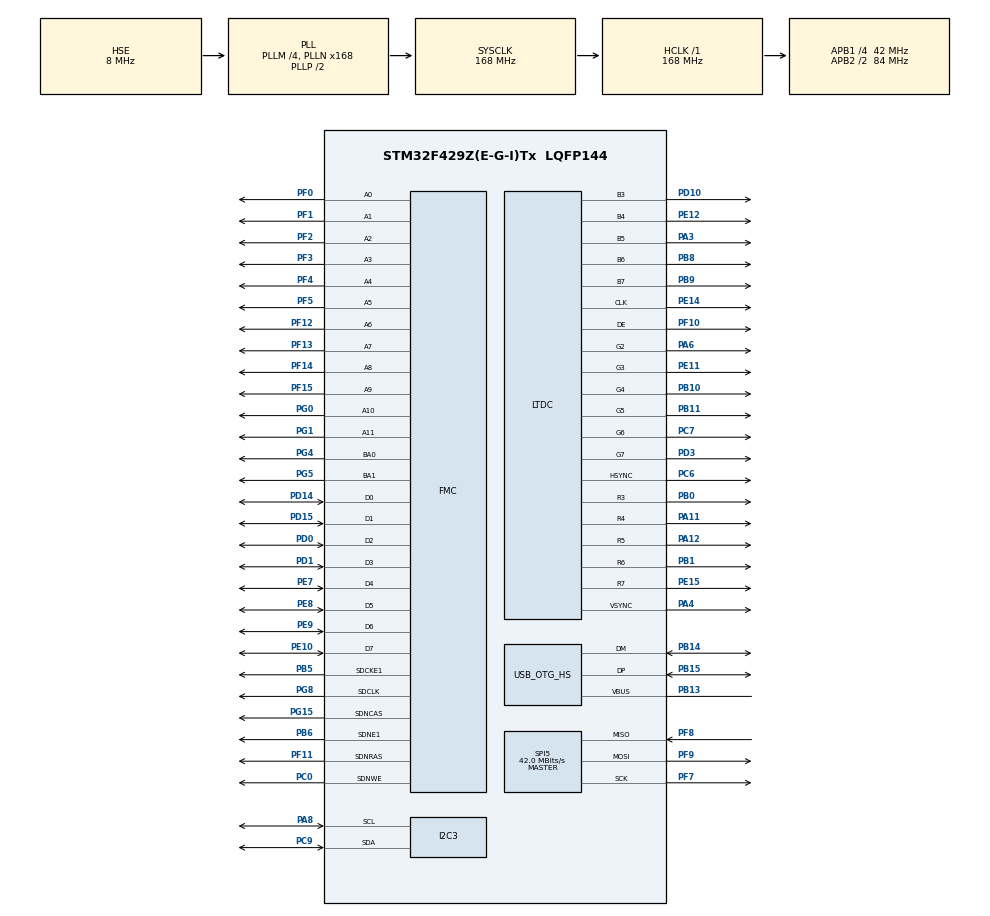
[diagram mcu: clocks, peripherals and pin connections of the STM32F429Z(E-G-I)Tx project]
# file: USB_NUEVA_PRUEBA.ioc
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DMA2D.ColorMode=DMA2D_OUTPUT_RGB565
FATFS._USE_STRFUNC=1
FREERTOS.Queues01=queue_usb,1,uint16_t,NULL,Dynamic,NULL,NULL
FREERTOS.Tasks01=USB,0,128,USB_TASK,Default,NULL,Dynamic,NULL,NULL;LCD,-3,128,LCD_TASK,Default,NULL,Dynamic,NULL,NULL
LTDC.ActiveH=240
LTDC.ActiveW=320
LTDC.PixelFormat_L0=LTDC_PIXEL_FORMAT_RGB565
LTDC.PixelFormat_L1=LTDC_PIXEL_FORMAT_RGB565
Mcu.Family=STM32F4
Mcu.Name=STM32F429Z(E-G-I)Tx
Mcu.Package=LQFP144
NVIC.OTG_HS_IRQn=true\:5\:0\:false\:false\:true\:true
NVIC.PriorityGroup=NVIC_PRIORITYGROUP_4
NVIC.TIM1_UP_TIM10_IRQn=true\:0\:0\:false\:false\:true\:false
NVIC.TimeBase=TIM1_UP_TIM10_IRQn
NVIC.TimeBaseIP=TIM1
PA11.Mode=RGB565
PA11.Signal=LTDC_R4
PA12.Mode=RGB565
PA12.Signal=LTDC_R5
PA13.Mode=Serial_Wire
PA13.Signal=SYS_JTMS-SWDIO
PA14.Mode=Serial_Wire
PA14.Signal=SYS_JTCK-SWCLK
PA3.Mode=RGB565
PA3.Signal=LTDC_B5
PA4.Mode=RGB565
PA4.Signal=LTDC_VSYNC
PA6.Mode=RGB565
PA6.Signal=LTDC_G2
PA8.Mode=I2C
PA8.Signal=I2C3_SCL
PB0.Mode=RGB565
PB0.Signal=LTDC_R3
PB1.Mode=RGB565
PB1.Signal=LTDC_R6
PB10.Mode=RGB565
PB10.Signal=LTDC_G4
PB11.Mode=RGB565
PB11.Signal=LTDC_G5
PB13.Mode=Activate_VBUS_FS
PB13.Signal=USB_OTG_HS_VBUS
PB14.Mode=Host_FS
PB14.Signal=USB_OTG_HS_DM
PB15.Mode=Host_FS
PB15.Signal=USB_OTG_HS_DP
PB5.Mode=SdramChipSelect2_1
PB5.Signal=FMC_SDCKE1
PB6.Mode=SdramChipSelect2_1
PB6.Signal=FMC_SDNE1
PB8.Mode=RGB565
PB8.Signal=LTDC_B6
PB9.Mode=RGB565
PB9.Signal=LTDC_B7
PC0.Signal=FMC_SDNWE
PC6.Mode=RGB565
PC6.Signal=LTDC_HSYNC
PC7.Mode=RGB565
PC7.Signal=LTDC_G6
PC9.Mode=I2C
PC9.Signal=I2C3_SDA
PD0.Signal=FMC_D2_DA2
PD1.Signal=FMC_D3_DA3
PD10.Mode=RGB565
PD10.Signal=LTDC_B3
PD14.Signal=FMC_D0_DA0
PD15.Signal=FMC_D1_DA1
PD3.Mode=RGB565
PD3.Signal=LTDC_G7
PE10.Signal=FMC_D7_DA7
PE11.Mode=RGB565
PE11.Signal=LTDC_G3
PE12.Mode=RGB565
PE12.Signal=LTDC_B4
PE14.Mode=RGB565
PE14.Signal=LTDC_CLK
PE15.Mode=RGB565
PE15.Signal=LTDC_R7
PE7.Signal=FMC_D4_DA4
PE8.Signal=FMC_D5_DA5
PE9.Signal=FMC_D6_DA6
PF0.Signal=FMC_A0
PF1.Signal=FMC_A1
PF10.Mode=RGB565
PF10.Signal=LTDC_DE
PF11.Signal=FMC_SDNRAS
PF12.Signal=FMC_A6
PF13.Signal=FMC_A7
PF14.Signal=FMC_A8
PF15.Signal=FMC_A9
PF2.Signal=FMC_A2
PF3.Signal=FMC_A3
PF4.Signal=FMC_A4
PF5.Signal=FMC_A5
PF7.Mode=Full_Duplex_Master
PF7.Signal=SPI5_SCK
PF8.Mode=Full_Duplex_Master
PF8.Signal=SPI5_MISO
PF9.Mode=Full_Duplex_Master
PF9.Signal=SPI5_MOSI
PG0.Signal=FMC_A10
PG1.Signal=FMC_A11
PG15.Signal=FMC_SDNCAS
PG4.Signal=FMC_A14_BA0
PG5.Signal=FMC_A15_BA1
PG8.Signal=FMC_SDCLK
PH0/OSC_IN.Mode=HSE-External-Oscillator
PH0/OSC_IN.Signal=RCC_OSC_IN
PH1/OSC_OUT.Mode=HSE-External-Oscillator
PH1/OSC_OUT.Signal=RCC_OSC_OUT
ProjectManager.HeapSize=0x200
ProjectManager.StackSize=0x400
ProjectManager.TargetToolchain=SW4STM32
RCC.48MHZClocksFreq_Value=48000000
RCC.AHBFreq_Value=168000000
RCC.APB1CLKDivider=RCC_HCLK_DIV4
RCC.APB1Freq_Value=42000000
RCC.APB1TimFreq_Value=84000000
RCC.APB2CLKDivider=RCC_HCLK_DIV2
RCC.APB2Freq_Value=84000000
RCC.APB2TimFreq_Value=168000000
RCC.CortexFreq_Value=168000000
RCC.HCLKFreq_Value=168000000
RCC.HSE_VALUE=8000000
RCC.HSI_VALUE=16000000
RCC.LSE_VALUE=32768
RCC.PLLM=4
RCC.PLLN=168
RCC.PLLQ=7
RCC.PLLSAIN=50
RCC.SYSCLKFreq_VALUE=168000000
RCC.SYSCLKSource=RCC_SYSCLKSOURCE_PLLCLK
RCC.VCOOutputFreq_Value=336000000
SH.FMC_A0.0=FMC_A0,12b-sda1
SH.FMC_A1.0=FMC_A1,12b-sda1
SH.FMC_A10.0=FMC_A10,12b-sda1
SH.FMC_A11.0=FMC_A11,12b-sda1
SH.FMC_A14_BA0.0=FMC_BA0,FourSdramBanks1
SH.FMC_A15_BA1.0=FMC_BA1,FourSdramBanks1
SH.FMC_A2.0=FMC_A2,12b-sda1
SH.FMC_A3.0=FMC_A3,12b-sda1
SH.FMC_A4.0=FMC_A4,12b-sda1
SH.FMC_A5.0=FMC_A5,12b-sda1
SH.FMC_A6.0=FMC_A6,12b-sda1
SH.FMC_A7.0=FMC_A7,12b-sda1
SH.FMC_A8.0=FMC_A8,12b-sda1
SH.FMC_A9.0=FMC_A9,12b-sda1
SH.FMC_D0_DA0.0=FMC_D0,sd-8b-d1
SH.FMC_D1_DA1.0=FMC_D1,sd-8b-d1
SH.FMC_D2_DA2.0=FMC_D2,sd-8b-d1
SH.FMC_D3_DA3.0=FMC_D3,sd-8b-d1
SH.FMC_D4_DA4.0=FMC_D4,sd-8b-d1
SH.FMC_D5_DA5.0=FMC_D5,sd-8b-d1
SH.FMC_D6_DA6.0=FMC_D6,sd-8b-d1
SH.FMC_D7_DA7.0=FMC_D7,sd-8b-d1
SH.FMC_SDCLK.0=FMC_SDCLK,12b-sda1
SH.FMC_SDNCAS.0=FMC_SDNCAS,12b-sda1
SH.FMC_SDNRAS.0=FMC_SDNRAS,12b-sda1
SH.FMC_SDNWE.0=FMC_SDNWE,12b-sda1
SPI5.CalculateBaudRate=42.0 MBits/s
SPI5.Direction=SPI_DIRECTION_2LINES
SPI5.Mode=SPI_MODE_MASTER
SPI5.VirtualType=VM_MASTER
USB_HOST.USBH_HandleTypeDef-MSC_HS=hUsbHostHS
USB_HOST.VirtualModeHS=Msc
USB_OTG_HS.VirtualMode-Host_FS=Host_FS
VP_DMA2D_VS_DMA2D.Mode=DMA2D_Activate
VP_FATFS_VS_USB.Mode=USB
VP_FREERTOS_VS_ENABLE.Mode=Enabled
VP_SYS_VS_tim1.Mode=TIM1
VP_USB_HOST_VS_USB_HOST_MSC_HS.Mode=MSC_HS
board=STM32F429I-DISC1

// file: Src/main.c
/**
  ******************************************************************************
  * File Name          : main.c
  * Description        : Main program body
  ******************************************************************************
  * This notice applies to any and all portions of this file
  * that are not between comment pairs USER CODE BEGIN and
  * USER CODE END. Other portions of this file, whether
  * inserted by the user or by software development tools
  * are owned by their respective copyright owners.
  *
  * Copyright (c) 2017 STMicroelectronics International N.V.
  * All rights reserved.
  *
  * Redistribution and use in source and binary forms, with or without
  * modification, are permitted, provided that the following conditions are met:
  *
  * 1. Redistribution of source code must retain the above copyright notice,
  *    this list of conditions and the following disclaimer.
  * 2. Redistributions in binary form must reproduce the above copyright notice,
  *    this list of conditions and the following disclaimer in the documentation
  *    and/or other materials provided with the distribution.
  * 3. Neither the name of STMicroelectronics nor the names of other
  *    contributors to this software may be used to endorse or promote products
  *    derived from this software without specific written permission.
  * 4. This software, including modifications and/or derivative works of this
  *    software, must execute solely and exclusively on microcontroller or
  *    microprocessor devices manufactured by or for STMicroelectronics.
  * 5. Redistribution and use of this software other than as permitted under
  *    this license is void and will automatically terminate your rights under
  *    this license.
  *
  * THIS SOFTWARE IS PROVIDED BY STMICROELECTRONICS AND CONTRIBUTORS "AS IS"
  * AND ANY EXPRESS, IMPLIED OR STATUTORY WARRANTIES, INCLUDING, BUT NOT
  * LIMITED TO, THE IMPLIED WARRANTIES OF MERCHANTABILITY, FITNESS FOR A
  * PARTICULAR PURPOSE AND NON-INFRINGEMENT OF THIRD PARTY INTELLECTUAL PROPERTY
  * RIGHTS ARE DISCLAIMED TO THE FULLEST EXTENT PERMITTED BY LAW. IN NO EVENT
  * SHALL STMICROELECTRONICS OR CONTRIBUTORS BE LIABLE FOR ANY DIRECT, INDIRECT,
  * INCIDENTAL, SPECIAL, EXEMPLARY, OR CONSEQUENTIAL DAMAGES (INCLUDING, BUT NOT
  * LIMITED TO, PROCUREMENT OF SUBSTITUTE GOODS OR SERVICES; LOSS OF USE, DATA,
  * OR PROFITS; OR BUSINESS INTERRUPTION) HOWEVER CAUSED AND ON ANY THEORY OF
  * LIABILITY, WHETHER IN CONTRACT, STRICT LIABILITY, OR TORT (INCLUDING
  * NEGLIGENCE OR OTHERWISE) ARISING IN ANY WAY OUT OF THE USE OF THIS SOFTWARE,
  * EVEN IF ADVISED OF THE POSSIBILITY OF SUCH DAMAGE.
  *
  ******************************************************************************
  */
#include "main.h"
#include "stm32f4xx_hal.h"
#include "cmsis_os.h"
#include "fatfs.h"
#include "usb_host.h"
#include "stm32f429i_discovery.h"
#include "stm32f429i_discovery_lcd.h"

DMA2D_HandleTypeDef hdma2d;

I2C_HandleTypeDef hi2c3;

LTDC_HandleTypeDef hltdc;

SPI_HandleTypeDef hspi5;

SDRAM_HandleTypeDef hsdram1;

osThreadId USBHandle;
osThreadId LCDHandle;

typedef enum {
  DISCONNECTION_EVENT = 1,
  CONNECTION_EVENT,
}MSC_ApplicationTypeDef;

osMessageQId queue_usbHandle;
/* USER CODE BEGIN PV */
/* Private variables ---------------------------------------------------------*/
static void MSC_Application(void);
/* USER CODE END 0 */
FATFS USBDISKFatFs;           /* File system object for USB disk logical drive */
FIL MyFile;                   /* File object */
char USBDISKPath[4];          /* USB Host logical drive path */
USBH_HandleTypeDef hUSB_Host; /* USB Host handle */
int contador=0;
int boton=0;
int bandera=0;
/*
* user callbak declaration
*/
static void USBH_UserProcess  (USBH_HandleTypeDef *phost, uint8_t id);
/* USER CODE END PV */
extern Diskio_drvTypeDef  USBH_Driver;
void SystemClock_Config(void);
static void MX_GPIO_Init(void);
static void MX_LTDC_Init(void);
static void MX_I2C3_Init(void);
static void MX_SPI5_Init(void);
static void MX_DMA2D_Init(void);
static void MX_FMC_Init(void);
void USB_TASK(void const * argument);
void LCD_TASK(void const * argument);

/* USER CODE BEGIN PFP */
/* Private function prototypes -----------------------------------------------*/

/* USER CODE END PFP */

int main(void)
{

  /* MCU Configuration----------------------------------------------------------*/

  /* Reset of all peripherals, Initializes the Flash interface and the Systick. */
  HAL_Init();

  /* Configure the system clock */
  SystemClock_Config();

  /* USER CODE BEGIN SysInit */
  BSP_LED_Init(LED3);
  BSP_LED_Init(LED4);
  BSP_PB_Init(BUTTON_KEY,BUTTON_MODE_GPIO);
  /* USER CODE END SysInit */

  /* Initialize all configured peripherals */
  MX_GPIO_Init();
  MX_LTDC_Init();
  MX_I2C3_Init();
  MX_SPI5_Init();
  MX_DMA2D_Init();
  MX_FMC_Init();

  /* Create the thread(s) */
  /* definition and creation of USB */
  osThreadDef(USB, USB_TASK, osPriorityNormal, 0, 8 * configMINIMAL_STACK_SIZE);
  USBHandle = osThreadCreate(osThread(USB), NULL);

  /* definition and creation of LCD */
  osThreadDef(LCD, LCD_TASK, osPriorityIdle, 0, 128);
  LCDHandle = osThreadCreate(osThread(LCD), NULL);

  /* Create the queue(s) */
  /* definition and creation of queue_usb */
  osMessageQDef(queue_usb, 1, uint16_t);
  queue_usbHandle = osMessageCreate(osMessageQ(queue_usb), NULL);

  /* Start scheduler */
  osKernelStart();

  /* We should never get here as control is now taken by the scheduler */

  /* Infinite loop */
  while (1)
  {

  }

}

/** System Clock Configuration
*/
void SystemClock_Config(void)
{

  RCC_OscInitTypeDef RCC_OscInitStruct;
  RCC_ClkInitTypeDef RCC_ClkInitStruct;
  RCC_PeriphCLKInitTypeDef PeriphClkInitStruct;

    /**Configure the main internal regulator output voltage
    */
  __HAL_RCC_PWR_CLK_ENABLE();

  __HAL_PWR_VOLTAGESCALING_CONFIG(PWR_REGULATOR_VOLTAGE_SCALE1);

    /**Initializes the CPU, AHB and APB busses clocks
    */
  RCC_OscInitStruct.OscillatorType = RCC_OSCILLATORTYPE_HSE;
  RCC_OscInitStruct.HSEState = RCC_HSE_ON;
  RCC_OscInitStruct.PLL.PLLState = RCC_PLL_ON;
  RCC_OscInitStruct.PLL.PLLSource = RCC_PLLSOURCE_HSE;
  RCC_OscInitStruct.PLL.PLLM = 4;
  RCC_OscInitStruct.PLL.PLLN = 168;
  RCC_OscInitStruct.PLL.PLLP = RCC_PLLP_DIV2;
  RCC_OscInitStruct.PLL.PLLQ = 7;
  if (HAL_RCC_OscConfig(&RCC_OscInitStruct) != HAL_OK)
  {
    _Error_Handler(__FILE__, __LINE__);
  }

    /**Initializes the CPU, AHB and APB busses clocks
    */
  RCC_ClkInitStruct.ClockType = RCC_CLOCKTYPE_HCLK|RCC_CLOCKTYPE_SYSCLK
                              |RCC_CLOCKTYPE_PCLK1|RCC_CLOCKTYPE_PCLK2;
  RCC_ClkInitStruct.SYSCLKSource = RCC_SYSCLKSOURCE_PLLCLK;
  RCC_ClkInitStruct.AHBCLKDivider = RCC_SYSCLK_DIV1;
  RCC_ClkInitStruct.APB1CLKDivider = RCC_HCLK_DIV4;
  RCC_ClkInitStruct.APB2CLKDivider = RCC_HCLK_DIV2;

  if (HAL_RCC_ClockConfig(&RCC_ClkInitStruct, FLASH_LATENCY_5) != HAL_OK)
  {
    _Error_Handler(__FILE__, __LINE__);
  }

  PeriphClkInitStruct.PeriphClockSelection = RCC_PERIPHCLK_LTDC;
  PeriphClkInitStruct.PLLSAI.PLLSAIN = 50;
  PeriphClkInitStruct.PLLSAI.PLLSAIR = 2;
  PeriphClkInitStruct.PLLSAIDivR = RCC_PLLSAIDIVR_2;
  if (HAL_RCCEx_PeriphCLKConfig(&PeriphClkInitStruct) != HAL_OK)
  {
    _Error_Handler(__FILE__, __LINE__);
  }

    /**Configure the Systick interrupt time
    */
  HAL_SYSTICK_Config(HAL_RCC_GetHCLKFreq()/1000);

    /**Configure the Systick
    */
  HAL_SYSTICK_CLKSourceConfig(SYSTICK_CLKSOURCE_HCLK);

  /* SysTick_IRQn interrupt configuration */
  HAL_NVIC_SetPriority(SysTick_IRQn, 15, 0);
}

/* DMA2D init function */
static void MX_DMA2D_Init(void)
{

  hdma2d.Instance = DMA2D;
  hdma2d.Init.Mode = DMA2D_M2M;
  hdma2d.Init.ColorMode = DMA2D_OUTPUT_RGB565;
  hdma2d.Init.OutputOffset = 0;
  hdma2d.LayerCfg[1].InputOffset = 0;
  hdma2d.LayerCfg[1].InputColorMode = DMA2D_INPUT_RGB565;
  hdma2d.LayerCfg[1].AlphaMode = DMA2D_NO_MODIF_ALPHA;
  hdma2d.LayerCfg[1].InputAlpha = 0;
  if (HAL_DMA2D_Init(&hdma2d) != HAL_OK)
  {
    _Error_Handler(__FILE__, __LINE__);
  }

  if (HAL_DMA2D_ConfigLayer(&hdma2d, 1) != HAL_OK)
  {
    _Error_Handler(__FILE__, __LINE__);
  }

}

/* I2C3 init function */
static void MX_I2C3_Init(void)
{

  hi2c3.Instance = I2C3;
  hi2c3.Init.ClockSpeed = 100000;
  hi2c3.Init.DutyCycle = I2C_DUTYCYCLE_2;
  hi2c3.Init.OwnAddress1 = 0;
  hi2c3.Init.AddressingMode = I2C_ADDRESSINGMODE_7BIT;
  hi2c3.Init.DualAddressMode = I2C_DUALADDRESS_DISABLE;
  hi2c3.Init.OwnAddress2 = 0;
  hi2c3.Init.GeneralCallMode = I2C_GENERALCALL_DISABLE;
  hi2c3.Init.NoStretchMode = I2C_NOSTRETCH_DISABLE;
  if (HAL_I2C_Init(&hi2c3) != HAL_OK)
  {
    _Error_Handler(__FILE__, __LINE__);
  }

}

/* LTDC init function */
static void MX_LTDC_Init(void)
{

  LTDC_LayerCfgTypeDef pLayerCfg;
  LTDC_LayerCfgTypeDef pLayerCfg1;

  hltdc.Instance = LTDC;
  hltdc.Init.HSPolarity = LTDC_HSPOLARITY_AL;
  hltdc.Init.VSPolarity = LTDC_VSPOLARITY_AL;
  hltdc.Init.DEPolarity = LTDC_DEPOLARITY_AL;
  hltdc.Init.PCPolarity = LTDC_PCPOLARITY_IPC;
  hltdc.Init.HorizontalSync = 7;
  hltdc.Init.VerticalSync = 3;
  hltdc.Init.AccumulatedHBP = 14;
  hltdc.Init.AccumulatedVBP = 5;
  hltdc.Init.AccumulatedActiveW = 334;
  hltdc.Init.AccumulatedActiveH = 245;
  hltdc.Init.TotalWidth = 340;
  hltdc.Init.TotalHeigh = 247;
  hltdc.Init.Backcolor.Blue = 0;
  hltdc.Init.Backcolor.Green = 0;
  hltdc.Init.Backcolor.Red = 0;
  if (HAL_LTDC_Init(&hltdc) != HAL_OK)
  {
    _Error_Handler(__FILE__, __LINE__);
  }

  pLayerCfg.WindowX0 = 0;
  pLayerCfg.WindowX1 = 0;
  pLayerCfg.WindowY0 = 0;
  pLayerCfg.WindowY1 = 0;
  pLayerCfg.PixelFormat = LTDC_PIXEL_FORMAT_RGB565;
  pLayerCfg.Alpha = 0;
  pLayerCfg.Alpha0 = 0;
  pLayerCfg.BlendingFactor1 = LTDC_BLENDING_FACTOR1_CA;
  pLayerCfg.BlendingFactor2 = LTDC_BLENDING_FACTOR2_CA;
  pLayerCfg.FBStartAdress = 0;
  pLayerCfg.ImageWidth = 0;
  pLayerCfg.ImageHeight = 0;
  pLayerCfg.Backcolor.Blue = 0;
  pLayerCfg.Backcolor.Green = 0;
  pLayerCfg.Backcolor.Red = 0;
  if (HAL_LTDC_ConfigLayer(&hltdc, &pLayerCfg, 0) != HAL_OK)
  {
    _Error_Handler(__FILE__, __LINE__);
  }

  pLayerCfg1.WindowX0 = 0;
  pLayerCfg1.WindowX1 = 0;
  pLayerCfg1.WindowY0 = 0;
  pLayerCfg1.WindowY1 = 0;
  pLayerCfg1.PixelFormat = LTDC_PIXEL_FORMAT_RGB565;
  pLayerCfg1.Alpha = 0;
  pLayerCfg1.Alpha0 = 0;
  pLayerCfg1.BlendingFactor1 = LTDC_BLENDING_FACTOR1_CA;
  pLayerCfg1.BlendingFactor2 = LTDC_BLENDING_FACTOR2_CA;
  pLayerCfg1.FBStartAdress = 0;
  pLayerCfg1.ImageWidth = 0;
  pLayerCfg1.ImageHeight = 0;
  pLayerCfg1.Backcolor.Blue = 0;
  pLayerCfg1.Backcolor.Green = 0;
  pLayerCfg1.Backcolor.Red = 0;
  if (HAL_LTDC_ConfigLayer(&hltdc, &pLayerCfg1, 1) != HAL_OK)
  {
    _Error_Handler(__FILE__, __LINE__);
  }

}

/* SPI5 init function */
static void MX_SPI5_Init(void)
{

  hspi5.Instance = SPI5;
  hspi5.Init.Mode = SPI_MODE_MASTER;
  hspi5.Init.Direction = SPI_DIRECTION_2LINES;
  hspi5.Init.DataSize = SPI_DATASIZE_8BIT;
  hspi5.Init.CLKPolarity = SPI_POLARITY_LOW;
  hspi5.Init.CLKPhase = SPI_PHASE_1EDGE;
  hspi5.Init.NSS = SPI_NSS_SOFT;
  hspi5.Init.BaudRatePrescaler = SPI_BAUDRATEPRESCALER_2;
  hspi5.Init.FirstBit = SPI_FIRSTBIT_MSB;
  hspi5.Init.TIMode = SPI_TIMODE_DISABLE;
  hspi5.Init.CRCCalculation = SPI_CRCCALCULATION_DISABLE;
  hspi5.Init.CRCPolynomial = 10;
  if (HAL_SPI_Init(&hspi5) != HAL_OK)
  {
    _Error_Handler(__FILE__, __LINE__);
  }

}
/* FMC initialization function */
static void MX_FMC_Init(void)
{
  FMC_SDRAM_TimingTypeDef SdramTiming;

  /** Perform the SDRAM1 memory initialization sequence
  */
  hsdram1.Instance = FMC_SDRAM_DEVICE;
  /* hsdram1.Init */
  hsdram1.Init.SDBank = FMC_SDRAM_BANK2;
  hsdram1.Init.ColumnBitsNumber = FMC_SDRAM_COLUMN_BITS_NUM_8;
  hsdram1.Init.RowBitsNumber = FMC_SDRAM_ROW_BITS_NUM_12;
  hsdram1.Init.MemoryDataWidth = FMC_SDRAM_MEM_BUS_WIDTH_8;
  hsdram1.Init.InternalBankNumber = FMC_SDRAM_INTERN_BANKS_NUM_4;
  hsdram1.Init.CASLatency = FMC_SDRAM_CAS_LATENCY_1;
  hsdram1.Init.WriteProtection = FMC_SDRAM_WRITE_PROTECTION_DISABLE;
  hsdram1.Init.SDClockPeriod = FMC_SDRAM_CLOCK_DISABLE;
  hsdram1.Init.ReadBurst = FMC_SDRAM_RBURST_DISABLE;
  hsdram1.Init.ReadPipeDelay = FMC_SDRAM_RPIPE_DELAY_0;
  /* SdramTiming */
  SdramTiming.LoadToActiveDelay = 16;
  SdramTiming.ExitSelfRefreshDelay = 16;
  SdramTiming.SelfRefreshTime = 16;
  SdramTiming.RowCycleDelay = 16;
  SdramTiming.WriteRecoveryTime = 16;
  SdramTiming.RPDelay = 16;
  SdramTiming.RCDDelay = 16;

  if (HAL_SDRAM_Init(&hsdram1, &SdramTiming) != HAL_OK)
  {
    _Error_Handler(__FILE__, __LINE__);
  }

}

/** Configure pins as
        * Analog
        * Input
        * Output
        * EVENT_OUT
        * EXTI
*/
static void MX_GPIO_Init(void)
{
  /* GPIO Ports Clock Enable */
  __HAL_RCC_GPIOF_CLK_ENABLE();
  __HAL_RCC_GPIOH_CLK_ENABLE();
  __HAL_RCC_GPIOC_CLK_ENABLE();
  __HAL_RCC_GPIOA_CLK_ENABLE();
  __HAL_RCC_GPIOB_CLK_ENABLE();
  __HAL_RCC_GPIOG_CLK_ENABLE();
  __HAL_RCC_GPIOE_CLK_ENABLE();
  __HAL_RCC_GPIOD_CLK_ENABLE();

}

/* USB_TASK function */
void USB_TASK(void const * argument)
{
  /* init code for USB_HOST */
	osEvent event;

	  /* Link the USB Host disk I/O driver */
	if(FATFS_LinkDriver(&USBH_Driver, USBDISKPath) == 0)
	  	  {
	  	    /* Init Host Library */
	  	    USBH_Init(&hUSB_Host, USBH_UserProcess, 0);

	  	    /* Add Supported Class */
	  	    USBH_RegisterClass(&hUSB_Host, USBH_MSC_CLASS);

	  	    /* Start Host Process */
	  	    USBH_Start(&hUSB_Host);

	    for( ;; )
	    {
	    	boton=BSP_PB_GetState(BUTTON_KEY);
			 if(boton!=0){
				 bandera=1;
			 }
	     if(bandera==1){
	      event = osMessageGet(queue_usbHandle, osWaitForever);

	      if(event.status == osEventMessage)
	      {
	        switch(event.value.v)
	        {
	        case CONNECTION_EVENT:
	        		MSC_Application();
	          break;

	        case DISCONNECTION_EVENT:
	        	osMessagePut(queue_usbHandle, CONNECTION_EVENT, 0);
	          break;

	        default:
	          break;
	        }
	      }

	    }
	     osDelay(10);
	    }
	  }

  /* USER CODE END 5 */
}

/* LCD_TASK function */
void LCD_TASK(void const * argument)
{
	BSP_LCD_Init();
	  BSP_LCD_LayerDefaultInit(LCD_BACKGROUND_LAYER, LCD_FRAME_BUFFER);
	  BSP_LCD_LayerDefaultInit(LCD_FOREGROUND_LAYER, LCD_FRAME_BUFFER);
	  BSP_LCD_SelectLayer(LCD_FOREGROUND_LAYER);
	  BSP_LCD_DisplayOn();
	  BSP_LCD_Clear(LCD_COLOR_WHITE);
	  /* USER CODE END 2 */

	  /* Infinite loop */
	  /* USER CODE BEGIN WHILE */
	  while (1)
	  {
		  BSP_LCD_SetTextColor(LCD_COLOR_DARKGREEN);
		  BSP_LCD_DisplayStringAtLine(1,(uint8_t*)"HOLA MUNDO 1");
		  osDelay(1000);
		  BSP_LCD_SetTextColor(LCD_COLOR_DARKBLUE);
		  BSP_LCD_DisplayStringAtLine(2,(uint8_t*)"HOLA MUNDO 2");
		  osDelay(1000);
		  BSP_LCD_SetTextColor(LCD_COLOR_BLACK);
		  BSP_LCD_DisplayStringAtLine(3,(uint8_t*)"HOLA MUNDO 3");
		  osDelay(1000);
		  BSP_LCD_SetTextColor(LCD_COLOR_DARKYELLOW);
		  BSP_LCD_DisplayStringAtLine(4,(uint8_t*)"HOLA MUNDO 4");
		  osDelay(1000);
		  BSP_LCD_SetTextColor(LCD_COLOR_DARKMAGENTA);
		  BSP_LCD_DisplayStringAtLine(5,(uint8_t*)"HOLA MUNDO 5");
		  osDelay(1000);
		  BSP_LCD_Clear(LCD_COLOR_WHITE);
		  osDelay(1000);

	  }
  /* USER CODE END LCD_TASK */
}

static void MSC_Application(void)
{

  FRESULT res;                                          /* FatFs function common result code */
  uint32_t byteswritten, bytesread;                     /* File write/read counts */
  uint8_t wtext[] = "HELLO WORLD"; /* File write buffer */
  uint8_t rtext[100];                                   /* File read buffer */

  /* Register the file system object to the FatFs module */
  if(f_mount(&USBDISKFatFs, (TCHAR const*)USBDISKPath, 0) == FR_OK)
  {
      /* Create and Open a new text file object with write access */
      if(open_append(&MyFile, "STM32.TXT") == FR_OK)
	  //if(f_open(&MyFile, "STM32_2.TXT", FA_CREATE_ALWAYS | FA_WRITE) != FR_OK)
      {
    	for(;;){
    	  BSP_LED_Off(LED3);
        /* Write data to the text file */
        res = f_write(&MyFile, wtext, sizeof(wtext), (void *)&byteswritten);
        f_printf(&MyFile, "\r\n");
        f_printf(&MyFile, "%d\r\n",contador);
        if(contador>254){
			BSP_LED_On(LED3);
			f_close(&MyFile);
			//FATFS_UnLinkDriver(USBDISKPath);
			bandera=0;
			osMessagePut(queue_usbHandle, DISCONNECTION_EVENT, 0);
		  }
		  else{
			osMessagePut(queue_usbHandle, CONNECTION_EVENT, 0);
		  }
		  contador++;
    	}

        /* Open the text file object with read access */
        /*if(f_open(&MyFile, "STM32.TXT", FA_READ) != FR_OK)
        {

          Error_Handler();
        }
        else
        {

          res = f_read(&MyFile, rtext, sizeof(rtext), (void *)&bytesread);

          if((bytesread == 0) || (res != FR_OK))
          {

            Error_Handler();
          }
          else
          {

            f_close(&MyFile);

            if(contador>254){
            	BSP_LED_On(LED3);
            	FATFS_UnLinkDriver(USBDISKPath);
            	osMessagePut(queue_usbHandle, DISCONNECTION_EVENT, 0);
            }
            else{
            	osMessagePut(queue_usbHandle, CONNECTION_EVENT, 0);
            }
            contador++;

          }
        }*/

    }
  }
}

static void USBH_UserProcess  (USBH_HandleTypeDef *phost, uint8_t id){
	switch(id)
	  {
	  case HOST_USER_SELECT_CONFIGURATION:
	    break;

	  case HOST_USER_DISCONNECTION:
	    BSP_LED_Off(LED3);
	    BSP_LED_Off(LED4);
	    osMessagePut(queue_usbHandle, DISCONNECTION_EVENT, 0);
	    break;

	  case HOST_USER_CLASS_ACTIVE:
	    osMessagePut(queue_usbHandle, CONNECTION_EVENT, 0);
	    break;

	  default:
	    break;
	  }
}
void HAL_TIM_PeriodElapsedCallback(TIM_HandleTypeDef *htim)
{
  if (htim->Instance == TIM1) {
    HAL_IncTick();
  }
}

void _Error_Handler(char * file, int line)
{
  while(1)
  {
  }
}

/************************ (C) COPYRIGHT STMicroelectronics *****END OF FILE****/
